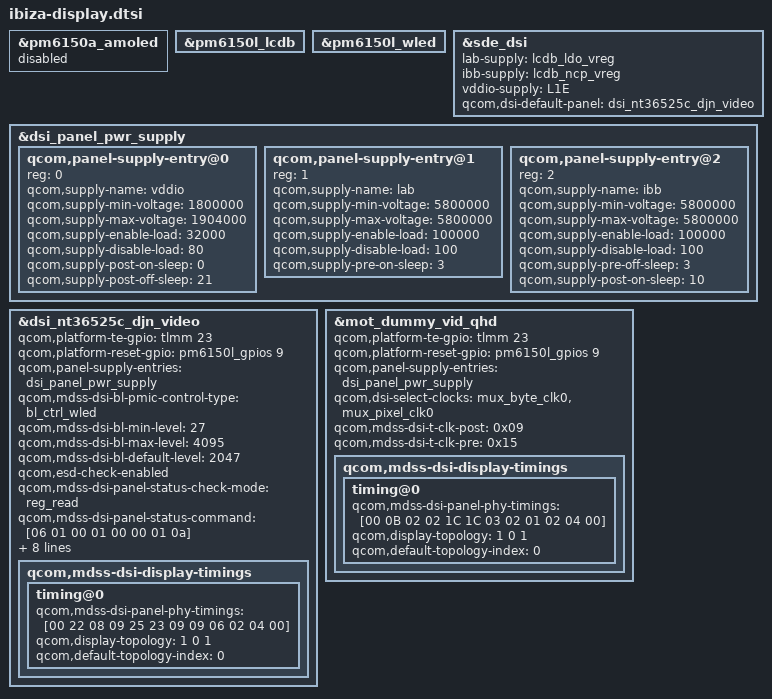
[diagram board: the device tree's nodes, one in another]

#include "dsi-panel-mot-djn-nt36525c-hd-video.dtsi"
#include "dsi-panel-mot-dummy-qhd-video.dtsi"



&pm6150a_amoled {
	status = "disabled";
};

&pm6150l_lcdb {
	status = "ok";
};

&pm6150l_wled {
	status = "ok";
};

&sde_dsi {
	lab-supply = <&lcdb_ldo_vreg>;
	ibb-supply = <&lcdb_ncp_vreg>;
	vddio-supply = <&L1E>;

	qcom,dsi-default-panel = <&dsi_nt36525c_djn_video>;
};

&dsi_panel_pwr_supply {
	qcom,panel-supply-entry@0 {
		reg = <0>;
		qcom,supply-name = "vddio";
		qcom,supply-min-voltage = <1800000>;
		qcom,supply-max-voltage = <1904000>;
		qcom,supply-enable-load = <32000>;
		qcom,supply-disable-load = <80>;
		qcom,supply-post-on-sleep= <0>;
		qcom,supply-post-off-sleep = <21>;
	};

	qcom,panel-supply-entry@1 {
		reg = <1>;
		qcom,supply-name = "lab";
		qcom,supply-min-voltage = <5800000>;
		qcom,supply-max-voltage = <5800000>;
		qcom,supply-enable-load = <100000>;
		qcom,supply-disable-load = <100>;
		qcom,supply-pre-on-sleep = <3>;
	};

	qcom,panel-supply-entry@2 {
		reg = <2>;
		qcom,supply-name = "ibb";
		qcom,supply-min-voltage = <5800000>;
		qcom,supply-max-voltage = <5800000>;
		qcom,supply-enable-load = <100000>;
		qcom,supply-disable-load = <100>;
		qcom,supply-pre-off-sleep = <3>;
		qcom,supply-post-on-sleep = <10>;
	};
};

&dsi_nt36525c_djn_video {
	qcom,platform-te-gpio = <&tlmm 23 0>;
	qcom,platform-reset-gpio = <&pm6150l_gpios 9 0>;

	qcom,panel-supply-entries = <&dsi_panel_pwr_supply>;

	qcom,mdss-dsi-bl-pmic-control-type = "bl_ctrl_wled";
	qcom,mdss-dsi-bl-min-level = <27>;
	qcom,mdss-dsi-bl-max-level = <4095>;
	qcom,mdss-dsi-bl-default-level = <2047>;

	qcom,esd-check-enabled;
	qcom,mdss-dsi-panel-status-check-mode = "reg_read";
	qcom,mdss-dsi-panel-status-command = [06 01 00 01 00 00 01 0a];
	qcom,mdss-dsi-panel-status-command-state = "dsi_hs_mode";
	qcom,mdss-dsi-panel-status-value = <0x9c>;
	qcom,mdss-dsi-panel-status-read-length = <1>;

	qcom,dsi-select-clocks = "mux_byte_clk0", "mux_pixel_clk0";
	qcom,mdss-dsi-t-clk-post = <0x0E>;
	qcom,mdss-dsi-t-clk-pre = <0x34>;
	qcom,mdss-dsi-display-timings {
		timing@0 {
			qcom,mdss-dsi-panel-phy-timings = [00 22 08 09 25 23 09
				09 06 02 04 00];
			qcom,display-topology = <1 0 1>;
			qcom,default-topology-index = <0>;
		};
	};
};

&mot_dummy_vid_qhd {
	qcom,platform-te-gpio = <&tlmm 23 0>;
	qcom,platform-reset-gpio = <&pm6150l_gpios 9 0>;

	qcom,panel-supply-entries = <&dsi_panel_pwr_supply>;

	qcom,dsi-select-clocks = "mux_byte_clk0", "mux_pixel_clk0";
	qcom,mdss-dsi-t-clk-post = <0x09>;
	qcom,mdss-dsi-t-clk-pre = <0x15>;
	qcom,mdss-dsi-display-timings {
		timing@0 {
			qcom,mdss-dsi-panel-phy-timings = [00 0B 02 02 1C 1C 03
							02 01 02 04 00];
			qcom,display-topology = <1 0 1>;
			qcom,default-topology-index = <0>;
		};
	};
};
